AUTOSAR XML (schema 00048)
package /AUTOLIV/SoftwareComponents/SCM
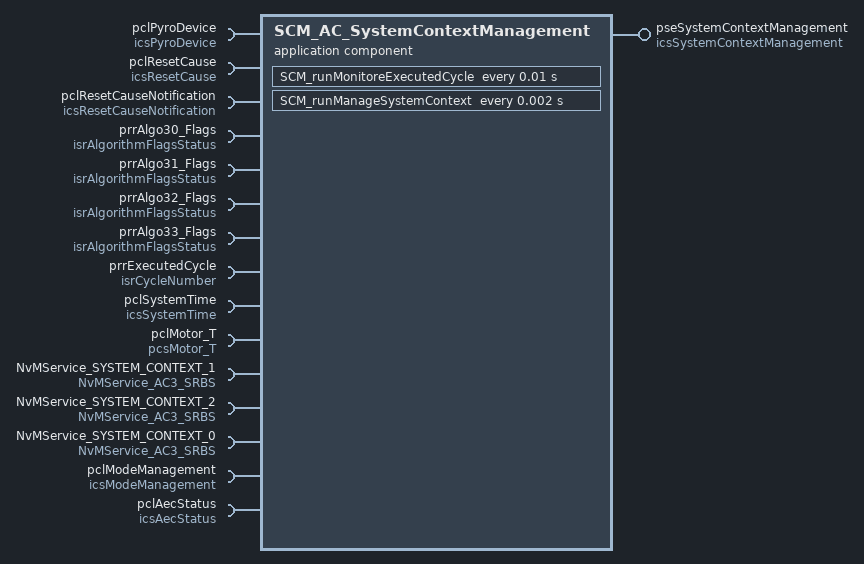
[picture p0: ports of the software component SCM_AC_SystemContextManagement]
  application sw component type SCM_AC_SystemContextManagement: category=SWC
    9 x require port:
      pclPyroDevice: client-com-spec=GetPyroActivationStatus, required-interface=icsPyroDevice
      pclResetCause: required-com-specs=[GetResetCause, ConfirmResetCause, DetermineResetCause], required-interface=icsResetCause
      pclResetCauseNotification: client-com-spec=NotifyResetCause, required-interface=icsResetCauseNotification
      prrAlgo30_Flags: required-interface=isrAlgorithmFlagsStatus
        required-com-specs:
          data-element=b8TriggerFlag, init-value=constant-reference=APPLINIT_KB8_ALGO_FLAG_FALSE
          data-element=b8InterruptFlag, init-value=constant-reference=APPLINIT_KB8_ALGO_FLAG_FALSE
          data-element=b8PreActivationFlag, init-value=constant-reference=APPLINIT_KB8_ALGO_FLAG_FALSE
          data-element=b8PreConditionsFlag, init-value=constant-reference=APPLINIT_KB8_ALGO_FLAG_FALSE
          data-element=u8TriggeringSource, init-value=constant-reference=APPLINIT_KU8_TRIGGERING_SOURCE_NO
      prrAlgo31_Flags: required-interface=isrAlgorithmFlagsStatus
        required-com-specs:
          data-element=b8TriggerFlag, init-value=constant-reference=APPLINIT_KB8_ALGO_FLAG_FALSE
          data-element=b8InterruptFlag, init-value=constant-reference=APPLINIT_KB8_ALGO_FLAG_FALSE
          data-element=b8PreActivationFlag, init-value=constant-reference=APPLINIT_KB8_ALGO_FLAG_FALSE
          data-element=b8PreConditionsFlag, init-value=constant-reference=APPLINIT_KB8_ALGO_FLAG_FALSE
          data-element=u8TriggeringSource, init-value=constant-reference=APPLINIT_KU8_TRIGGERING_SOURCE_NO
      prrAlgo32_Flags: required-interface=isrAlgorithmFlagsStatus
        required-com-specs:
          data-element=b8TriggerFlag, init-value=constant-reference=APPLINIT_KB8_ALGO_FLAG_FALSE
          data-element=b8InterruptFlag, init-value=constant-reference=APPLINIT_KB8_ALGO_FLAG_FALSE
          data-element=b8PreActivationFlag, init-value=constant-reference=APPLINIT_KB8_ALGO_FLAG_FALSE
          data-element=b8PreConditionsFlag, init-value=constant-reference=APPLINIT_KB8_ALGO_FLAG_FALSE
          data-element=u8TriggeringSource, init-value=constant-reference=APPLINIT_KU8_TRIGGERING_SOURCE_NO
      prrAlgo33_Flags: required-interface=isrAlgorithmFlagsStatus
        required-com-specs:
          data-element=b8TriggerFlag, init-value=constant-reference=APPLINIT_KB8_ALGO_FLAG_FALSE
          data-element=b8InterruptFlag, init-value=constant-reference=APPLINIT_KB8_ALGO_FLAG_FALSE
          data-element=b8PreActivationFlag, init-value=constant-reference=APPLINIT_KB8_ALGO_FLAG_FALSE
          data-element=b8PreConditionsFlag, init-value=constant-reference=APPLINIT_KB8_ALGO_FLAG_FALSE
          data-element=u8TriggeringSource, init-value=constant-reference=APPLINIT_KU8_TRIGGERING_SOURCE_NO
      prrExecutedCycle: nonqueued-receiver-com-spec{data-element=u8CycleNumber, init-value=constant-reference=APPLINIT_KU8_CYCLE_NUMBER_NONE}, required-interface=isrCycleNumber
      pclSystemTime: required-com-specs=[ReadRelativeSystemTime, WriteRelativeSystemTime, ReadAbsoluteSystemTime, WriteAbsoluteSystemTime], required-interface=icsSystemTime
    provide port pseSystemContextManagement: provided-interface=icsSystemContextManagement
      provided-com-specs:
        operation=GetLastTensionningState, queue-length=1
        operation=GetMonitoredCycle, queue-length=1
        operation=ManageSystemContextStorage, queue-length=1
        operation=RestoreSystemContext, queue-length=1
        operation=SuperviseKL30bg, queue-length=1
        operation=GetBatteryHysteresisThrs, queue-length=1
    6 x require port:
      pclMotor_T: required-com-specs=[GetDeficiencyLevel, InitializeDeficiencyLevel], required-interface=pcsMotor_T
      NvMService_SYSTEM_CONTEXT_1: required-com-specs=[EraseBlock, InvalidateNvBlock, WriteBlock, ReadBlock, SetRamBlockStatus, GetErrorStatus], required-interface=NvMService_AC3_SRBS
      NvMService_SYSTEM_CONTEXT_2: required-com-specs=[EraseBlock, InvalidateNvBlock, WriteBlock, ReadBlock, SetRamBlockStatus, GetErrorStatus], required-interface=NvMService_AC3_SRBS
      NvMService_SYSTEM_CONTEXT_0: required-com-specs=[EraseBlock, InvalidateNvBlock, WriteBlock, ReadBlock, SetRamBlockStatus, GetErrorStatus], required-interface=NvMService_AC3_SRBS
      pclModeManagement: client-com-spec=CheckModeStatus, required-interface=icsModeManagement
      pclAecStatus: required-interface=icsAecStatus
        required-com-specs:
          SetAecEvent
          GetNumberOfImplementedAec
          GetAecStatus
          GetAecQualificationCount
          GetAecNvpBlockRecordingStatus
          GetAecGroupsStatus
          GetAecDeskillThrs
    behavior SCM_IB_SystemContextManagement: data-type-mapping=DataTypeMappingSet_PP4G, handle-termination-and-restart=NO-SUPPORT
      timing event SCM_evMonitoreExecutedCycle: start-on-event=SCM_runMonitoreExecutedCycle, period=0.01
      timing event SCM_evPeriodicEvent: start-on-event=SCM_runManageSystemContext, period=0.002
      4 x operation invoked event:
        SCM_evGetLastTensioningState: start-on-event=SCM_runGetLastTensioningState, operation=pseSystemContextManagement.GetLastTensionningState
        SCM_evSuperviseKL30bg: start-on-event=SCM_runKL30bgSupervision, operation=pseSystemContextManagement.SuperviseKL30bg
        SCM_evManageSystemContextStorage: start-on-event=SCM_runManageSystemContextStorage, operation=pseSystemContextManagement.ManageSystemContextStorage
        oie_pseSystemContextManagement_GetBatteryHysteresisThrs: start-on-event=SCM_runGetBatteryHysteresisThrs, operation=pseSystemContextManagement.GetBatteryHysteresisThrs
      init event SCM_runRestoreSystemContext_InitEvent: start-on-event=SCM_runRestoreSystemContext
      explicit-inter-runnable-variables:
        data u8CurrentTensioningState: step-size=0, sw-calibration-access=READ-ONLY, type=u8CycleNumberType_Appl, init-value=constant-reference=APPLINIT_KU8_CYCLE_NUMBER_NONE
        data u8LastTensioningSituation: step-size=0, sw-calibration-access=READ-ONLY, type=u8CycleNumberType_Appl, init-value=constant-reference=APPLINIT_KU8_CYCLE_NUMBER_NONE
      8 x runnable:
        SCM_runGetBatteryHysteresisThrs
        SCM_runGetLastTensioningState: sw-addr-method=CODE, can-be-invoked-concurrently=true
          read-local-variables:
            access u8LastTensioningSituation: accessed-variable=u8LastTensioningSituation
        SCM_runKL30bgSupervision: sw-addr-method=CODE, can-be-invoked-concurrently=true
        SCM_runManageSystemContext: sw-addr-method=CODE, can-be-invoked-concurrently=true
          data-receive-point-by-arguments:
            5 x access:
              DRP_prrExecutedCycle_u8CycleNumber: accessed-variable=prrExecutedCycle.u8CycleNumber
              drparg_b8InterruptFlag10: accessed-variable=prrAlgo32_Flags.b8InterruptFlag
              drparg_b8InterruptFlag11: accessed-variable=prrAlgo33_Flags.b8InterruptFlag
              drparg_b8InterruptFlag8: accessed-variable=prrAlgo30_Flags.b8InterruptFlag
              drparg_b8InterruptFlag9: accessed-variable=prrAlgo31_Flags.b8InterruptFlag
          read-local-variables:
            access rd_u8CurrentTensioningState: accessed-variable=u8CurrentTensioningState
          6 x sync call:
            scp_GetPyroActivationStatus: operation=pclPyroDevice.GetPyroActivationStatus
            SSCP_pclSystemTime_ReadAbsoluteSystemTime: operation=pclSystemTime.ReadAbsoluteSystemTime
            SC_pclMotor_T_GetDeficiencyLevel: operation=pclMotor_T.GetDeficiencyLevel
            SC_pclMotor_T_InitializeDeficiencyLevel: operation=pclMotor_T.InitializeDeficiencyLevel
            SC_pclAecStatus_GetAecStatus: operation=pclAecStatus.GetAecStatus
            SC_pclAecStatus_SetAecEvent: operation=pclAecStatus.SetAecEvent
          written-local-variables:
            access wr_u8CurrentTensioningState: accessed-variable=u8CurrentTensioningState
        SCM_runManageSystemContextStorage: sw-addr-method=CODE, can-be-invoked-concurrently=true
          15 x sync call:
            SC_NvMService_SYSTEM_CONTEXT_0_EraseBlock: operation=NvMService_SYSTEM_CONTEXT_0.EraseBlock
            SC_NvMService_SYSTEM_CONTEXT_0_InvalidateNvBlock: operation=NvMService_SYSTEM_CONTEXT_0.InvalidateNvBlock
            SC_NvMService_SYSTEM_CONTEXT_1_EraseBlock: operation=NvMService_SYSTEM_CONTEXT_1.EraseBlock
            SC_NvMService_SYSTEM_CONTEXT_1_InvalidateNvBlock: operation=NvMService_SYSTEM_CONTEXT_1.InvalidateNvBlock
            SC_NvMService_SYSTEM_CONTEXT_2_EraseBlock: operation=NvMService_SYSTEM_CONTEXT_2.EraseBlock
            SC_NvMService_SYSTEM_CONTEXT_2_InvalidateNvBlock: operation=NvMService_SYSTEM_CONTEXT_2.InvalidateNvBlock
            SC_NvMService_SYSTEM_CONTEXT_0_GetErrorStatus: operation=NvMService_SYSTEM_CONTEXT_0.GetErrorStatus
            SC_NvMService_SYSTEM_CONTEXT_0_ReadBlock: operation=NvMService_SYSTEM_CONTEXT_0.ReadBlock
            SC_NvMService_SYSTEM_CONTEXT_0_WriteBlock: operation=NvMService_SYSTEM_CONTEXT_0.WriteBlock
            SC_NvMService_SYSTEM_CONTEXT_1_GetErrorStatus: operation=NvMService_SYSTEM_CONTEXT_1.GetErrorStatus
            SC_NvMService_SYSTEM_CONTEXT_1_ReadBlock: operation=NvMService_SYSTEM_CONTEXT_1.ReadBlock
            SC_NvMService_SYSTEM_CONTEXT_1_WriteBlock: operation=NvMService_SYSTEM_CONTEXT_1.WriteBlock
            SC_NvMService_SYSTEM_CONTEXT_2_GetErrorStatus: operation=NvMService_SYSTEM_CONTEXT_2.GetErrorStatus
            SC_NvMService_SYSTEM_CONTEXT_2_ReadBlock: operation=NvMService_SYSTEM_CONTEXT_2.ReadBlock
            SC_NvMService_SYSTEM_CONTEXT_2_WriteBlock: operation=NvMService_SYSTEM_CONTEXT_2.WriteBlock
        SCM_runMonitoreExecutedCycle
          sync call SC_pclModeManagement_CheckModeStatus: operation=pclModeManagement.CheckModeStatus
        SCM_runRestoreSystemContext: sw-addr-method=CODE, can-be-invoked-concurrently=true
          sync call SSCP_pclResetCauseNotification_NotifyResetCause: operation=pclResetCauseNotification.NotifyResetCause
          sync call SSCP_pclResetCause_GetResetCause: operation=pclResetCause.GetResetCause
          written-local-variables:
            access u8LastTensioningSituation: accessed-variable=u8LastTensioningSituation
        SCM_runRestoreValueSystemContext
          read-local-variables:
            access u8LastTensioningSituation: accessed-variable=u8LastTensioningSituation
          written-local-variables:
            access u8LastTensioningSituation1: accessed-variable=u8LastTensioningSituation
  swc implementation SCM_impSystemContextManagement: behavior=SCM_IB_SystemContextManagement
    code-descriptors:
      code SCM_Impl_Code: artifact-descriptors=autosar-engineering-object={short-label=SCM_Impl_Code_CodeDesc, category=SWSRC}
